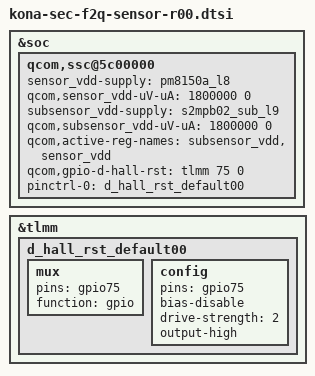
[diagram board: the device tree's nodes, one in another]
/* Copyright (c) 2016-2017, The Linux Foundation. All rights reserved.
 *
 * This program is free software; you can redistribute it and/or modify
 * it under the terms of the GNU General Public License version 2 and
 * only version 2 as published by the Free Software Foundation.
 *
 * This program is distributed in the hope that it will be useful,
 * but WITHOUT ANY WARRANTY; without even the implied warranty of
 * MERCHANTABILITY or FITNESS FOR A PARTICULAR PURPOSE.  See the
 * GNU General Public License for more details.
 */

&soc {
        /delete-node/ qcom,ssc@5c00000;

	qcom,ssc@5c00000 {
		sensor_vdd-supply = <&pm8150a_l8>;
		qcom,sensor_vdd-uV-uA = <1800000 0>;
		subsensor_vdd-supply = <&s2mpb02_sub_l9>;
		qcom,subsensor_vdd-uV-uA = <1800000 0>;
		qcom,active-reg-names = "subsensor_vdd", "sensor_vdd";

		qcom,gpio-d-hall-rst = <&tlmm 75 0>;
		pinctrl-names = "default";
		pinctrl-0 = <&d_hall_rst_default00>;	
	};
};

&tlmm {
	d_hall_rst_default00: d_hall_rst_default00 {
		mux {
			pins = "gpio75";
			function = "gpio";
		};

		config {
			pins = "gpio75";
			bias-disable; /* No PULL */
			drive-strength = <2>; /* 2 MA */
			output-high;
		};
	};
};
